# MM32F013x register map
File version: 1.01
CPU: CM0 r0p0, little endian, no MPU, no FPU, 2 interrupt priority bits
Registers are 32-bit, read-write, reset 0x0 unless marked. A register's access mark holds for its fields unless they carry their own. Offsets are from the block's base; lines under a group give offsets from that group; [hi:lo] are bit positions; {n}, {i} and the like mark numbered series; 'fields as' and 'values as' point back to an identical list; <NAME> marks a mode.

## Memory map
0x1FFFF7E8 DEVICE size 0x400
0x40000000 TIM2 size 0x400 — General purpose timer
0x40000400 TIM3 size 0x400 — General purpose timer
0x40002800 RTC size 0x30 — Real time clock
0x40002840 BKP size 0x2E0 — Backup registers
0x40002C00 WWDG size 0x60 — Window watchdog
0x40003000 IWDG size 0x400 — Independent watchdog
0x40003800 SPI2 size 0x400
0x40004400 UART2 size 0x400
0x40005400 I2C1 size 0x400 — Inter integrated circuit
0x40005C00 USB size 0x400 — Universal serial bus full-speed device interface
0x40006400 CAN size 0x400 — Controller area network
0x40006800 CSM size 0x40 — Debug support
0x40007000 PWR size 0x400 — Power control
0x40010000 EXTI size 0x800 — External interrupt/event controller
0x40012400 ADC1 size 0x400 — Analog to digital converter 1
0x40012C00 TIM1 size 0x400 — Advanced timer
0x40013000 SPI1 size 0x400 — Serial peripheral interface
0x40013400 DBG size 0x40 — Debug support
0x40013800 UART1 size 0x400 — Universal asynchronous receiver transmitter
0x40013C00 COMP size 0x400 — Comparator
0x40014000 TIM14 size 0x400 — Basic purpose timer
0x40014400 TIM16 size 0x400 — Basic purpose timer
0x40014800 TIM17 size 0x400
0x40020000 DMA1 size 0x400 — Direct Momory Accessuart
0x40021000 RCC size 0x400 — Reset and clock control
0x40022000 FLASH size 0x400
0x40023000 CRC size 0x400 — CRC calculation unit
0x40030000 HWDIV size 0x400 — Hardware divider
0x48000000 GPIOA size 0x400 — General purpose I/O
0x48000400 GPIOB size 0x400
0x48000800 GPIOC size 0x400
0x48000C00 GPIOD size 0x400

## Interrupts
0 WWDG_IWDG (WWDG) — Watchdog interrupt
1 PVD (PWR) — PVD through EXTI line detection interrupt
2 RTC_BKP (RTC) — RTC and BKP global interrupt
3 FLASH — Flash global interrupt
4 RCC — RCC global interrupt
5 EXTI0_1 (EXTI) — EXTI Line0_1 interrupt
6 EXTI2_3 (EXTI) — EXTI Line2_3 interrupt
7 EXTI4_15 (EXTI) — EXTI Line4_15 interrupt
8 HWDIV — HWDIV global interrupt
9 DMA1_Channel1 (DMA1) — DMA1 Channel1 global interrupt
10 DMA1_Channel2_3 (DMA1) — DMA1 Channel2_3 global interrupt
11 DMA1_Channel4_5 (DMA1) — DMA1 Channel4_5 global interrupt
12 ADC1_COMP (ADC1) — ADC1 and compare global interrupt
13 TIM1_BRK_UP_TRG_COM (TIM1) — TIM1 break,Update,Trigger and Commutation interrupt
14 TIM1_CC (TIM1) — TIM1 Capture Compare interrupt
15 TIM2 — TIM2 global interrupt
16 TIM3 — TIM3 global interrupt
19 TIM14 — TIM14 global interrupt
21 TIM16 — TIM16 global interrupt
22 TIM17 — TIM17 global interrupt
23 I2C1 — I2C1 interrupt
25 SPI1 — SPI1 global interrupt
26 SPI2 — SPI2 global interrupt
27 UART1 — UART1 global interrupt
28 UART2 — UART2 global interrupt
30 CAN — CAN interrupts
31 USB_FS (USB) — USB Device FS

## ADC1 — Analog to digital converter 1
Base 0x40012400
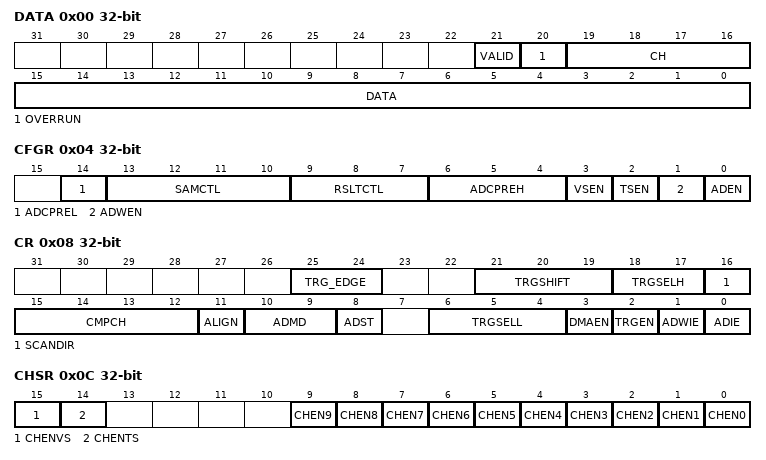
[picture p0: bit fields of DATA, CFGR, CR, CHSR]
0x00 DATA ro
  [21] VALID — Valid flag
  [20] OVERRUN — Overrun flag
  [19:16] CH — ADC current channel convert data
  [15:0] DATA — Transfer data
0x04 CFGR — Configure register
  [14] ADCPREL — ADC low prescaler coefficient
  [13:10] SAMCTL — Channel x Sample time selection
  [9:7] RSLTCTL — Resolution
  [6:4] ADCPREH — ADC high prescaler coefficient
  [3] VSEN — Reference voltage enable
  [2] TSEN — Temperature sensor enable
  [1] ADWEN — ADC window comparison enable
  [0] ADEN — ADC enable
0x08 CR — Control register
  [25:24] TRG_EDGE — Trigger edge selection
  [21:19] TRGSHIFT — External trigger shift sample
  [18:17] TRGSELH — External trigger selection high
  [16] SCANDIR — ADC scan direction
  [15:12] CMPCH — Window comparison channel selection
  [11] ALIGN — Data alignment
  [10:9] ADMD — ADC mode
  [8] ADST — ADC start
  [6:4] TRGSELL — External trigger selection low
  [3] DMAEN — Direct memory access enable
  [2] TRGEN — External trigger enable
  [1] ADWIE — ADC window comparator interrupt enable
  [0] ADIE — ADC interrupt enable
0x0C CHSR — Channel select register
  [15] CHENVS — Internal reference voltage channel enable
  [14] CHENTS — Temperature Sensor channel enable
  [n] CHEN{n} (n=0..9) — Analog input channel {n} enable
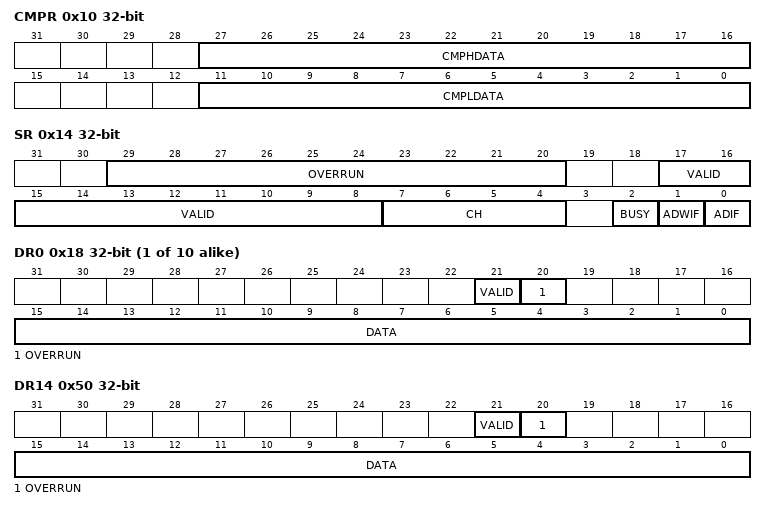
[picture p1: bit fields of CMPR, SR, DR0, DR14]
0x10 CMPR — Compare register
  [27:16] CMPHDATA — Compare data high limit
  [11:0] CMPLDATA — Compare data low limit
0x14 SR ro — Status register
  [29:20] OVERRUN — Overrun flag
  [17:8] VALID — Valid flag
  [7:4] CH — Current conversion channel
  [2] BUSY
  [1] ADWIF — ADC window comparator interrupt flag
  [0] ADIF — ADC interrupt flag
{0x18+4i} DR{i} ro (i=0..9) — Channel {i} data register
  [21] VALID — Valid flag
  [20] OVERRUN — Overrun flag
  [15:0] DATA — Transfer data
0x50 DR14 ro — Channel 14 data register
  fields as DR0
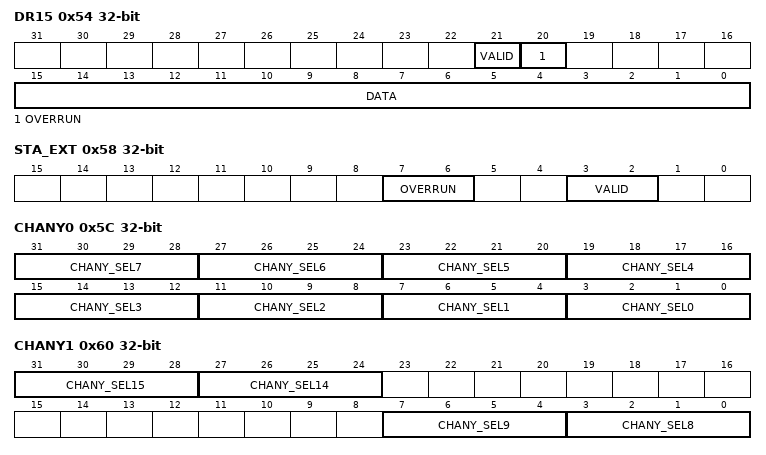
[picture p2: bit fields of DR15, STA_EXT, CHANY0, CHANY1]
0x54 DR15 ro — Channel 15 data register
  fields as DR0
0x58 STA_EXT ro — Extended status register
  [7:6] OVERRUN — Overrun flag
  [3:2] VALID — Valid flag
0x5C CHANY0 — Arbitrary channel channel selection register 0
  [4n+3:4n] CHANY_SEL{n} (n=0..7) — Can be configured as any channel from ch0 to 9, 14 to 15.
0x60 CHANY1 — Arbitrary channel channel selection register 1
  [31:28] CHANY_SEL15 — Can be configured as any channel from ch0 to 9, 14 to 15.
  [27:24] CHANY_SEL14 — Can be configured as any channel from ch0 to 9, 14 to 15.
  [7:4] CHANY_SEL9 — Can be configured as any channel from ch0 to 9, 14 to 15.
  [3:0] CHANY_SEL8 — Can be configured as any channel from ch0 to 9, 14 to 15.
0x64 ANY_CFG — Arbitrary channel configuration register
  [3:0] CHANY_NUM — channel number configuration
0x68 ANY_CR — Arbitrary channel control register
  [0] CHANY_MDEN — Any channel configuration mode enable bit
